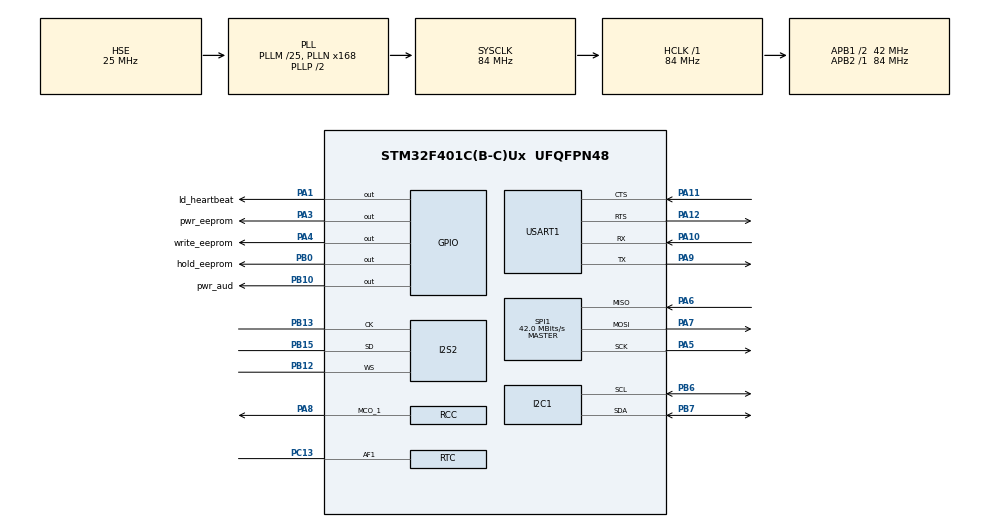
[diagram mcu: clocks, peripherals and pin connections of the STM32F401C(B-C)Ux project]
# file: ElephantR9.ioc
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Dma.Request0=SPI2_TX
Dma.SPI2_TX.0.Direction=DMA_MEMORY_TO_PERIPH
Dma.SPI2_TX.0.FIFOMode=DMA_FIFOMODE_DISABLE
Dma.SPI2_TX.0.Instance=DMA1_Stream4
Dma.SPI2_TX.0.MemDataAlignment=DMA_MDATAALIGN_HALFWORD
Dma.SPI2_TX.0.MemInc=DMA_MINC_ENABLE
Dma.SPI2_TX.0.Mode=DMA_NORMAL
Dma.SPI2_TX.0.PeriphDataAlignment=DMA_PDATAALIGN_HALFWORD
Dma.SPI2_TX.0.PeriphInc=DMA_PINC_DISABLE
Dma.SPI2_TX.0.Priority=DMA_PRIORITY_LOW
I2S2.AudioFreq=I2S_AUDIOFREQ_96K
I2S2.DataFormat=I2S_DATAFORMAT_32B
I2S2.ErrorAudioFreq=-2.34 %
I2S2.FullDuplexMode=I2S_FULLDUPLEXMODE_DISABLE
I2S2.Instance=SPI$Index
I2S2.RealAudioFreq=93.75 KHz
I2S2.Standard=I2S_STANDARD_MSB
I2S2.VirtualMode=I2S_MODE_MASTER
Mcu.Family=STM32F4
Mcu.Name=STM32F401C(B-C)Ux
Mcu.Package=UFQFPN48
NVIC.DMA1_Stream4_IRQn=true\:0\:0\:false\:false\:true\:false\:true\:true
NVIC.PriorityGroup=NVIC_PRIORITYGROUP_4
NVIC.RTC_Alarm_IRQn=true\:0\:0\:false\:false\:true\:true\:true\:true
PA0-WKUP.GPIO_Label=sw_tilt
PA0-WKUP.Mode=SYS_WakeUp0
PA0-WKUP.Signal=SYS_WKUP
PA1.GPIO_Label=ld_heartbeat
PA1.Signal=GPIO_Output
PA10.Mode=Asynchronous
PA10.Signal=USART1_RX
PA11.Mode=CTS_RTS
PA11.Signal=USART1_CTS
PA12.Mode=CTS_RTS
PA12.Signal=USART1_RTS
PA13.Mode=JTAG_5_pins
PA13.Signal=SYS_JTMS-SWDIO
PA14.Mode=JTAG_5_pins
PA14.Signal=SYS_JTCK-SWCLK
PA15.Mode=JTAG_5_pins
PA15.Signal=SYS_JTDI
PA3.GPIO_Label=pwr_eeprom
PA3.Signal=GPIO_Output
PA4.GPIO_Label=write_eeprom
PA4.Signal=GPIO_Output
PA5.Mode=Full_Duplex_Master
PA5.Signal=SPI1_SCK
PA6.Mode=Full_Duplex_Master
PA6.Signal=SPI1_MISO
PA7.Mode=Full_Duplex_Master
PA7.Signal=SPI1_MOSI
PA8.Mode=Clock-out-1
PA8.Signal=RCC_MCO_1
PA9.Mode=Asynchronous
PA9.Signal=USART1_TX
PB0.GPIO_Label=hold_eeprom
PB0.Signal=GPIO_Output
PB10.GPIO_Label=pwr_aud
PB10.Signal=GPIO_Output
PB12.Mode=Half_Duplex_Master
PB12.Signal=I2S2_WS
PB13.Mode=Half_Duplex_Master
PB13.Signal=I2S2_CK
PB15.Mode=Half_Duplex_Master
PB15.Signal=I2S2_SD
PB3.Mode=JTAG_5_pins
PB3.Signal=SYS_JTDO-SWO
PB4.Mode=JTAG_5_pins
PB4.Signal=SYS_JTRST
PB6.Mode=I2C
PB6.Signal=I2C1_SCL
PB7.Mode=I2C
PB7.Signal=I2C1_SDA
PC13-ANTI_TAMP.Mode=AlarmA_RoutedAF
PC13-ANTI_TAMP.Signal=RTC_AF1
PC14-OSC32_IN.Mode=LSE-External-Oscillator
PC14-OSC32_IN.Signal=RCC_OSC32_IN
PC15-OSC32_OUT.Mode=LSE-External-Oscillator
PC15-OSC32_OUT.Signal=RCC_OSC32_OUT
PH0\ -\ OSC_IN.Mode=HSE-External-Oscillator
PH0\ -\ OSC_IN.Signal=RCC_OSC_IN
PH1\ -\ OSC_OUT.Mode=HSE-External-Oscillator
PH1\ -\ OSC_OUT.Signal=RCC_OSC_OUT
ProjectManager.HeapSize=0x200
ProjectManager.StackSize=0x400
ProjectManager.TargetToolchain=Makefile
RCC.48MHZClocksFreq_Value=42000000
RCC.AHBFreq_Value=84000000
RCC.APB1CLKDivider=RCC_HCLK_DIV2
RCC.APB1Freq_Value=42000000
RCC.APB1TimFreq_Value=84000000
RCC.APB2Freq_Value=84000000
RCC.APB2TimFreq_Value=84000000
RCC.CortexFreq_Value=84000000
RCC.HCLKFreq_Value=84000000
RCC.HSE_VALUE=25000000
RCC.HSI_VALUE=16000000
RCC.PLLI2SR=4
RCC.PLLM=25
RCC.PLLN=168
RCC.PLLSourceVirtual=RCC_PLLSOURCE_HSE
RCC.SYSCLKFreq_VALUE=84000000
RCC.SYSCLKSource=RCC_SYSCLKSOURCE_PLLCLK
RCC.VCOOutputFreq_Value=168000000
RTC.Alarm=RTC_ALARM_A
RTC.AlarmMaskDateWeekDay=RTC_ALARMMASK_DATEWEEKDAY
RTC.AlarmMaskHours=RTC_ALARMMASK_HOURS
RTC.AlarmMaskMinutes=RTC_ALARMMASK_MINUTES
RTC.Format=RTC_FORMAT_BCD
RTC.OutPutPolarity=RTC_OUTPUT_POLARITY_LOW
RTC.OutPutType=RTC_OUTPUT_TYPE_PUSHPULL
RTC.Seconds_A=10
SPI1.BaudRatePrescaler=SPI_BAUDRATEPRESCALER_2
SPI1.CalculateBaudRate=42.0 MBits/s
SPI1.Direction=SPI_DIRECTION_2LINES
SPI1.Mode=SPI_MODE_MASTER
SPI1.VirtualNSS=VM_NSSHARD
SPI1.VirtualType=VM_MASTER
USART1.VirtualMode=VM_ASYNC
VP_RTC_VS_RTC_Activate.Mode=RTC_Enabled
VP_RTC_VS_RTC_Calendar.Mode=RTC_Calendar
board=custom

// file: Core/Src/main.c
/* USER CODE BEGIN Header */
/**
  ******************************************************************************
  * @file           : main.c
  * @brief          : Main program body
  ******************************************************************************
  * @attention
  *
  * Copyright (c) 2023 STMicroelectronics.
  * All rights reserved.
  *
  * This software is licensed under terms that can be found in the LICENSE file
  * in the root directory of this software component.
  * If no LICENSE file comes with this software, it is provided AS-IS.
  *
  ******************************************************************************
  */
/* USER CODE END Header */
#include "main.h"

I2C_HandleTypeDef hi2c1;

I2S_HandleTypeDef hi2s2;
DMA_HandleTypeDef hdma_spi2_tx;

RTC_HandleTypeDef hrtc;

SPI_HandleTypeDef hspi1;

UART_HandleTypeDef huart1;

/* USER CODE BEGIN PV */
volatile uint8_t state_alrm = 0;
/* USER CODE END PV */

void SystemClock_Config(void);
static void MX_GPIO_Init(void);
static void MX_DMA_Init(void);
static void MX_I2C1_Init(void);
static void MX_I2S2_Init(void);
static void MX_SPI1_Init(void);
static void MX_USART1_UART_Init(void);
static void MX_RTC_Init(void);

int main(void)
{

  /* MCU Configuration--------------------------------------------------------*/

  /* Reset of all peripherals, Initializes the Flash interface and the Systick. */
  HAL_Init();

  /* Configure the system clock */
  SystemClock_Config();

  /* Initialize all configured peripherals */
  MX_GPIO_Init();
  MX_DMA_Init();
  MX_I2C1_Init();
  MX_I2S2_Init();
  MX_SPI1_Init();
  MX_USART1_UART_Init();
  MX_RTC_Init();
  /* USER CODE BEGIN 2 */
  /*if(state_alrm) {
      state_alrm = 0;
      HAL_GPIO_TogglePin(usr_led_GPIO_Port,usr_led_Pin);
    } */

  /* USER CODE END 2 */

  /* Infinite loop */
  while (1)
  {

  }
}

void SystemClock_Config(void)
{
  RCC_OscInitTypeDef RCC_OscInitStruct = {0};
  RCC_ClkInitTypeDef RCC_ClkInitStruct = {0};

  /** Configure the main internal regulator output voltage
  */
  __HAL_RCC_PWR_CLK_ENABLE();
  __HAL_PWR_VOLTAGESCALING_CONFIG(PWR_REGULATOR_VOLTAGE_SCALE2);

  /** Initializes the RCC Oscillators according to the specified parameters
  * in the RCC_OscInitTypeDef structure.
  */
  RCC_OscInitStruct.OscillatorType = RCC_OSCILLATORTYPE_HSI|RCC_OSCILLATORTYPE_LSI
                              |RCC_OSCILLATORTYPE_HSE;
  RCC_OscInitStruct.HSEState = RCC_HSE_ON;
  RCC_OscInitStruct.HSIState = RCC_HSI_ON;
  RCC_OscInitStruct.HSICalibrationValue = RCC_HSICALIBRATION_DEFAULT;
  RCC_OscInitStruct.LSIState = RCC_LSI_ON;
  RCC_OscInitStruct.PLL.PLLState = RCC_PLL_ON;
  RCC_OscInitStruct.PLL.PLLSource = RCC_PLLSOURCE_HSE;
  RCC_OscInitStruct.PLL.PLLM = 25;
  RCC_OscInitStruct.PLL.PLLN = 168;
  RCC_OscInitStruct.PLL.PLLP = RCC_PLLP_DIV2;
  RCC_OscInitStruct.PLL.PLLQ = 4;
  if (HAL_RCC_OscConfig(&RCC_OscInitStruct) != HAL_OK)
  {
    Error_Handler();
  }

  /** Initializes the CPU, AHB and APB buses clocks
  */
  RCC_ClkInitStruct.ClockType = RCC_CLOCKTYPE_HCLK|RCC_CLOCKTYPE_SYSCLK
                              |RCC_CLOCKTYPE_PCLK1|RCC_CLOCKTYPE_PCLK2;
  RCC_ClkInitStruct.SYSCLKSource = RCC_SYSCLKSOURCE_PLLCLK;
  RCC_ClkInitStruct.AHBCLKDivider = RCC_SYSCLK_DIV1;
  RCC_ClkInitStruct.APB1CLKDivider = RCC_HCLK_DIV2;
  RCC_ClkInitStruct.APB2CLKDivider = RCC_HCLK_DIV1;

  if (HAL_RCC_ClockConfig(&RCC_ClkInitStruct, FLASH_LATENCY_2) != HAL_OK)
  {
    Error_Handler();
  }
  HAL_RCC_MCOConfig(RCC_MCO1, RCC_MCO1SOURCE_HSI, RCC_MCODIV_1);
}

static void MX_I2C1_Init(void)
{

  hi2c1.Instance = I2C1;
  hi2c1.Init.ClockSpeed = 100000;
  hi2c1.Init.DutyCycle = I2C_DUTYCYCLE_2;
  hi2c1.Init.OwnAddress1 = 0;
  hi2c1.Init.AddressingMode = I2C_ADDRESSINGMODE_7BIT;
  hi2c1.Init.DualAddressMode = I2C_DUALADDRESS_DISABLE;
  hi2c1.Init.OwnAddress2 = 0;
  hi2c1.Init.GeneralCallMode = I2C_GENERALCALL_DISABLE;
  hi2c1.Init.NoStretchMode = I2C_NOSTRETCH_DISABLE;
  if (HAL_I2C_Init(&hi2c1) != HAL_OK)
  {
    Error_Handler();
  }

}

static void MX_I2S2_Init(void)
{

  hi2s2.Instance = SPI2;
  hi2s2.Init.Mode = I2S_MODE_MASTER_TX;
  hi2s2.Init.Standard = I2S_STANDARD_PCM_SHORT;
  hi2s2.Init.DataFormat = I2S_DATAFORMAT_16B;
  hi2s2.Init.MCLKOutput = I2S_MCLKOUTPUT_DISABLE;
  hi2s2.Init.AudioFreq = I2S_AUDIOFREQ_96K;
  hi2s2.Init.CPOL = I2S_CPOL_LOW;
  hi2s2.Init.ClockSource = I2S_CLOCK_PLL;
  hi2s2.Init.FullDuplexMode = I2S_FULLDUPLEXMODE_DISABLE;
  if (HAL_I2S_Init(&hi2s2) != HAL_OK)
  {
    Error_Handler();
  }

}

static void MX_RTC_Init(void)
{

  RTC_TimeTypeDef sTime = {0};
  RTC_DateTypeDef sDate = {0};
  RTC_AlarmTypeDef sAlarm = {0};

  /** Initialize RTC Only
  */
  hrtc.Instance = RTC;
  hrtc.Init.HourFormat = RTC_HOURFORMAT_24;
  hrtc.Init.AsynchPrediv = 127;
  hrtc.Init.SynchPrediv = 255;
  hrtc.Init.OutPut = RTC_OUTPUT_ALARMA;
  hrtc.Init.OutPutPolarity = RTC_OUTPUT_POLARITY_LOW;
  hrtc.Init.OutPutType = RTC_OUTPUT_TYPE_PUSHPULL;
  if (HAL_RTC_Init(&hrtc) != HAL_OK)
  {
    Error_Handler();
  }

  /** Initialize RTC and set the Time and Date
  */
  sTime.Hours = 0x0;
  sTime.Minutes = 0x0;
  sTime.Seconds = 0x0;
  sTime.DayLightSaving = RTC_DAYLIGHTSAVING_NONE;
  sTime.StoreOperation = RTC_STOREOPERATION_RESET;
  if (HAL_RTC_SetTime(&hrtc, &sTime, RTC_FORMAT_BCD) != HAL_OK)
  {
    Error_Handler();
  }
  sDate.WeekDay = RTC_WEEKDAY_MONDAY;
  sDate.Month = RTC_MONTH_JANUARY;
  sDate.Date = 0x1;
  sDate.Year = 0x0;

  if (HAL_RTC_SetDate(&hrtc, &sDate, RTC_FORMAT_BCD) != HAL_OK)
  {
    Error_Handler();
  }

  /** Enable the Alarm A
  */
  sAlarm.AlarmTime.Hours = 0x0;
  sAlarm.AlarmTime.Minutes = 0x0;
  sAlarm.AlarmTime.Seconds = 0x10;
  sAlarm.AlarmTime.SubSeconds = 0x0;
  sAlarm.AlarmTime.DayLightSaving = RTC_DAYLIGHTSAVING_NONE;
  sAlarm.AlarmTime.StoreOperation = RTC_STOREOPERATION_RESET;
  sAlarm.AlarmMask = RTC_ALARMMASK_DATEWEEKDAY|RTC_ALARMMASK_HOURS
                              |RTC_ALARMMASK_MINUTES;
  sAlarm.AlarmSubSecondMask = RTC_ALARMSUBSECONDMASK_ALL;
  sAlarm.AlarmDateWeekDaySel = RTC_ALARMDATEWEEKDAYSEL_DATE;
  sAlarm.AlarmDateWeekDay = 0x1;
  sAlarm.Alarm = RTC_ALARM_A;
  if (HAL_RTC_SetAlarm_IT(&hrtc, &sAlarm, RTC_FORMAT_BCD) != HAL_OK)
  {
    Error_Handler();
  }

}

static void MX_SPI1_Init(void)
{

  /* SPI1 parameter configuration*/
  hspi1.Instance = SPI1;
  hspi1.Init.Mode = SPI_MODE_MASTER;
  hspi1.Init.Direction = SPI_DIRECTION_2LINES;
  hspi1.Init.DataSize = SPI_DATASIZE_8BIT;
  hspi1.Init.CLKPolarity = SPI_POLARITY_LOW;
  hspi1.Init.CLKPhase = SPI_PHASE_1EDGE;
  hspi1.Init.NSS = SPI_NSS_SOFT;
  hspi1.Init.BaudRatePrescaler = SPI_BAUDRATEPRESCALER_2;
  hspi1.Init.FirstBit = SPI_FIRSTBIT_MSB;
  hspi1.Init.TIMode = SPI_TIMODE_DISABLE;
  hspi1.Init.CRCCalculation = SPI_CRCCALCULATION_DISABLE;
  hspi1.Init.CRCPolynomial = 10;
  if (HAL_SPI_Init(&hspi1) != HAL_OK)
  {
    Error_Handler();
  }

}

static void MX_USART1_UART_Init(void)
{

  huart1.Instance = USART1;
  huart1.Init.BaudRate = 115200;
  huart1.Init.WordLength = UART_WORDLENGTH_8B;
  huart1.Init.StopBits = UART_STOPBITS_1;
  huart1.Init.Parity = UART_PARITY_NONE;
  huart1.Init.Mode = UART_MODE_TX_RX;
  huart1.Init.HwFlowCtl = UART_HWCONTROL_RTS_CTS;
  huart1.Init.OverSampling = UART_OVERSAMPLING_16;
  if (HAL_UART_Init(&huart1) != HAL_OK)
  {
    Error_Handler();
  }

}

static void MX_DMA_Init(void)
{

  /* DMA controller clock enable */
  __HAL_RCC_DMA1_CLK_ENABLE();

  /* DMA interrupt init */
  /* DMA1_Stream4_IRQn interrupt configuration */
  HAL_NVIC_SetPriority(DMA1_Stream4_IRQn, 0, 0);
  HAL_NVIC_EnableIRQ(DMA1_Stream4_IRQn);

}

static void MX_GPIO_Init(void)
{
  GPIO_InitTypeDef GPIO_InitStruct = {0};

  /* GPIO Ports Clock Enable */
  __HAL_RCC_GPIOC_CLK_ENABLE();
  __HAL_RCC_GPIOH_CLK_ENABLE();
  __HAL_RCC_GPIOA_CLK_ENABLE();
  __HAL_RCC_GPIOB_CLK_ENABLE();

  /*Configure GPIO pin Output Level */
  HAL_GPIO_WritePin(GPIOA, ld_heartbeat_Pin|pwr_eeprom_Pin|write_eeprom_Pin, GPIO_PIN_RESET);

  /*Configure GPIO pin Output Level */
  HAL_GPIO_WritePin(GPIOB, hold_eeprom_Pin|pwr_aud_Pin, GPIO_PIN_RESET);

  /*Configure GPIO pins : ld_heartbeat_Pin pwr_eeprom_Pin write_eeprom_Pin */
  GPIO_InitStruct.Pin = ld_heartbeat_Pin|pwr_eeprom_Pin|write_eeprom_Pin;
  GPIO_InitStruct.Mode = GPIO_MODE_OUTPUT_PP;
  GPIO_InitStruct.Pull = GPIO_NOPULL;
  GPIO_InitStruct.Speed = GPIO_SPEED_FREQ_LOW;
  HAL_GPIO_Init(GPIOA, &GPIO_InitStruct);

  /*Configure GPIO pins : hold_eeprom_Pin pwr_aud_Pin */
  GPIO_InitStruct.Pin = hold_eeprom_Pin|pwr_aud_Pin;
  GPIO_InitStruct.Mode = GPIO_MODE_OUTPUT_PP;
  GPIO_InitStruct.Pull = GPIO_NOPULL;
  GPIO_InitStruct.Speed = GPIO_SPEED_FREQ_LOW;
  HAL_GPIO_Init(GPIOB, &GPIO_InitStruct);

  /*Configure GPIO pin : PA8 */
  GPIO_InitStruct.Pin = GPIO_PIN_8;
  GPIO_InitStruct.Mode = GPIO_MODE_AF_PP;
  GPIO_InitStruct.Pull = GPIO_NOPULL;
  GPIO_InitStruct.Speed = GPIO_SPEED_FREQ_LOW;
  GPIO_InitStruct.Alternate = GPIO_AF0_MCO;
  HAL_GPIO_Init(GPIOA, &GPIO_InitStruct);

}

/* USER CODE BEGIN 4 */
void HAL_RTC_AlarmAEventCallback(RTC_HandleTypeDef *hrtc) {

}
/* USER CODE END 4 */

void Error_Handler(void)
{
  __disable_irq();
  while (1)
  {
  }
}
